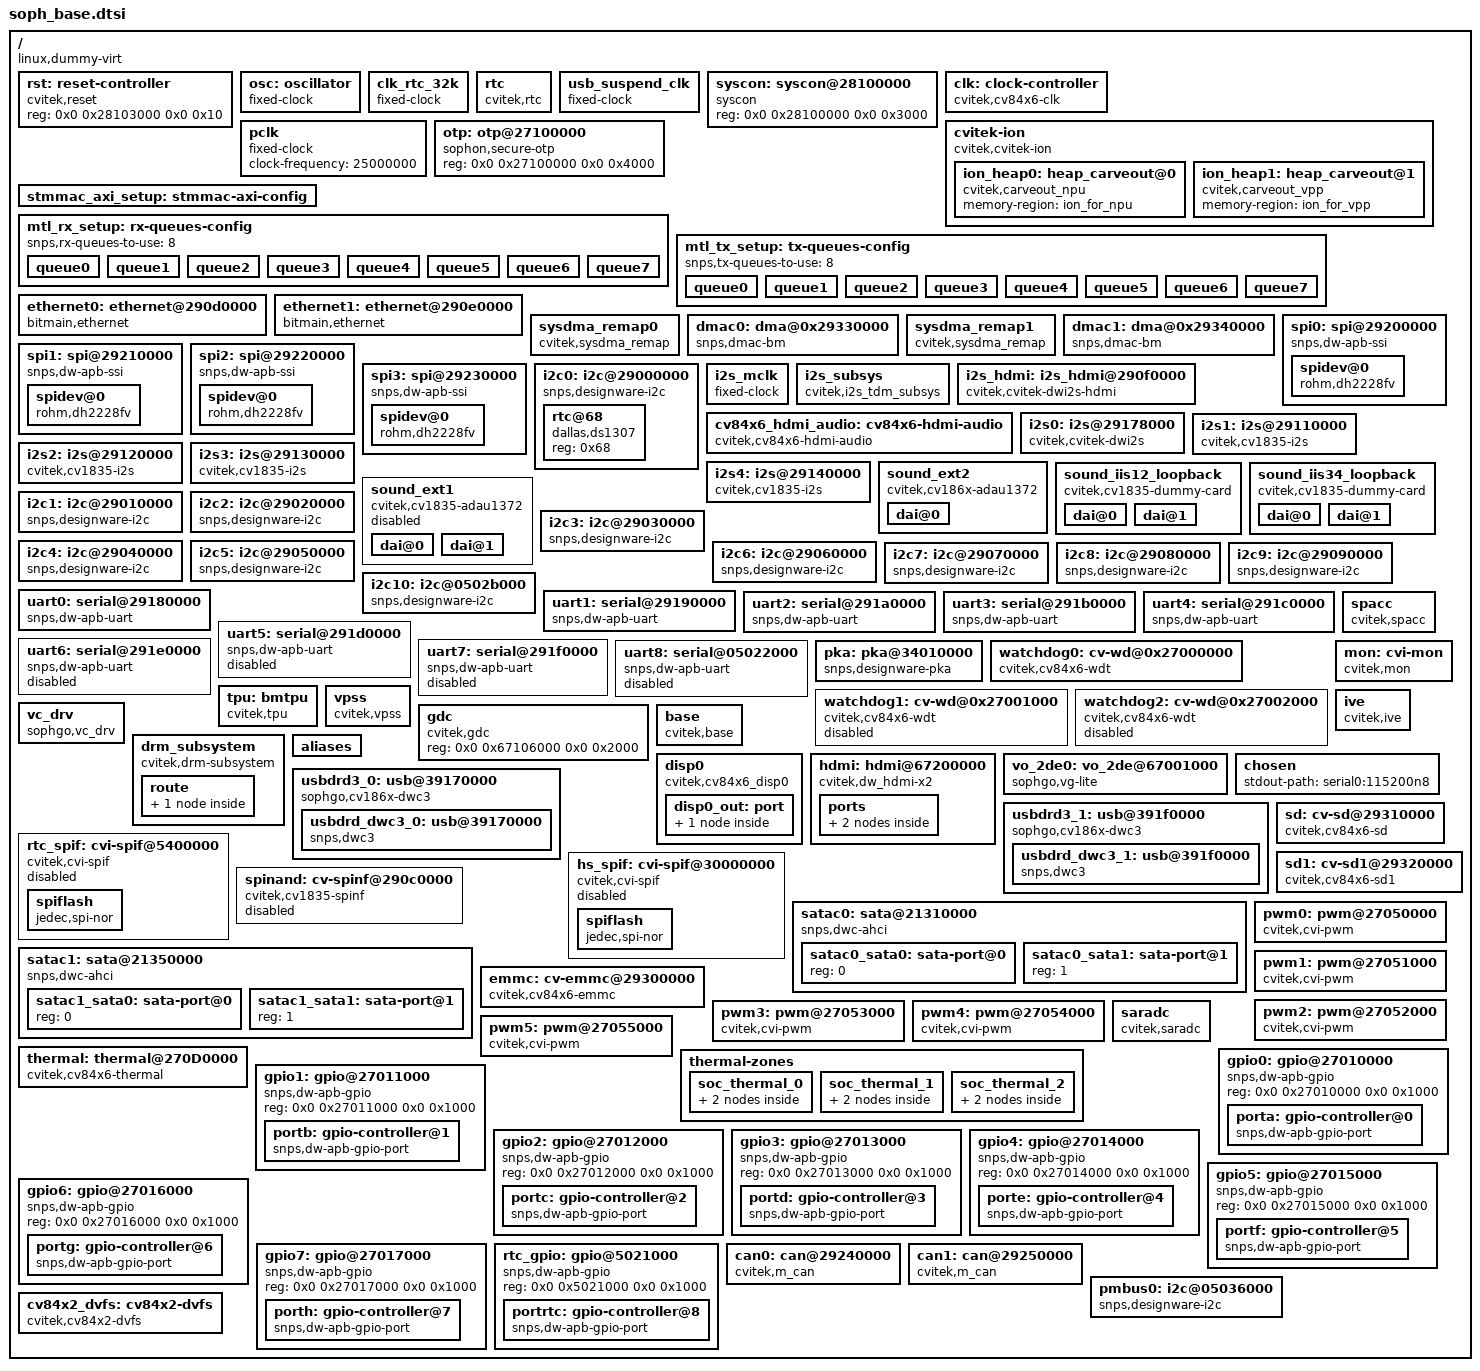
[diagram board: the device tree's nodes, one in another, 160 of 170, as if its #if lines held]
#include <dt-bindings/interrupt-controller/arm-gic.h>
#include <dt-bindings/gpio/gpio.h>
#include <dt-bindings/clock/cv84x6-clock.h>
#include <dt-bindings/reset/cv186x-resets.h>
#include <dt-bindings/dma/cv84x6-dmamap.h>

#include "cv84x6-pinctrl.dtsi"
#include "cv84x6-pcie.dtsi"

/ {
	compatible = "linux,dummy-virt";
	#size-cells = <0x2>;
	#address-cells = <0x2>;

	serial-number = "FFFFFFFFFFFFFFFFFFFFFFFFFFFFFFFF";

	rst: reset-controller {
		#reset-cells = <1>;
		compatible = "cvitek,reset";
		reg = <0x0 0x28103000 0x0 0x10>;
	};

	osc: oscillator {
		#clock-cells = <0>;
		compatible = "fixed-clock";
		clock-frequency = <25000000>;
		clock-output-names = "osc";
	};

	clk_rtc_32k: clk_rtc_32k {
		#clock-cells = <0>;
		compatible = "fixed-clock";
		clock-frequency = <32768>;
		clock-output-names = "clk_rtc_32k";
	};

	rtc {
		compatible = "cvitek,rtc";
		reg = <0x0 0x05026000 0x0 0xF00>, <0x0 0x05025000 0x0 0x1000>;
	};

	usb_suspend_clk: usb_suspend_clk {
		#clock-cells = <0>;
		compatible = "fixed-clock";
		clock-frequency = <200000>;
		clock-output-names = "usb_suspend_clk";
	};

	syscon: syscon@28100000 {
		compatible = "syscon", "simple-mfd";
		reg = <0x0 0x28100000 0x0 0x3000>;
	};

	clk: clock-controller {
		compatible = "cvitek,cv84x6-clk";
		clocks = <&osc>;
		#clock-cells = <1>;
		syscon = <&syscon>;
	};

#ifndef __UBOOT__
	cvitek-ion {
		compatible = "cvitek,cvitek-ion";

		ion_heap0: heap_carveout@0 {
			compatible = "cvitek,carveout_npu";
			memory-region = <&ion_for_npu>;
		};

		ion_heap1: heap_carveout@1 {
			compatible = "cvitek,carveout_vpp";
			memory-region = <&ion_for_vpp>;
		};
	};
#endif

	pclk: pclk {
		#clock-cells = <0>;
		compatible = "fixed-clock";
		clock-frequency = <25000000>;
	};

	otp: otp@27100000 {
                compatible = "sophon,secure-otp";
                reg = <0x0 0x27100000 0x0 0x4000>;
                #address-cells = <1>;
                #size-cells = <1>;
        };

	stmmac_axi_setup: stmmac-axi-config {
		snps,wr_osr_lmt = <1>;
		snps,rd_osr_lmt = <2>;
		snps,blen = <4 8 16 0 0 0 0>;
	};

	mtl_rx_setup: rx-queues-config {
		snps,rx-queues-to-use = <8>;
		queue0 {};
		queue1 {};
		queue2 {};
		queue3 {};
		queue4 {};
		queue5 {};
		queue6 {};
		queue7 {};
	};

	mtl_tx_setup: tx-queues-config {
		snps,tx-queues-to-use = <8>;
		queue0 {};
		queue1 {};
		queue2 {};
		queue3 {};
		queue4 {};
		queue5 {};
		queue6 {};
		queue7 {};
	};

	ethernet0: ethernet@290d0000 {
		compatible = "bitmain,ethernet";
		reg = <0x0 0x290d0000 0x0 0x4000>;
		reg-names = "mac";

		clock-names = "clk_tx", "stmmaceth", "ptp_ref";
		clocks = <&clk CV84X6_CLK_ETH0_TX>,
			   <&clk CV84X6_CLK_AXI4_ETH0>,
			   <&clk CV84X6_CLK_ETH0_PTP_REF>;
		// resets= <&rst RST_ETH0>;
		// reset-names = "stmmaceth";
#ifdef __UBOOT__
		phy-reset-gpios = <&porta 6 0>;
#endif
		/* no hash filter and perfect filter support */
		snps,multicast-filter-bins = <0>;
		snps,perfect-filter-entries = <1>;

		snps,txpbl = <32>;
		snps,rxpbl = <32>;
		snps,aal;

		snps,axi-config = <&stmmac_axi_setup>;
		snps,mtl-rx-config = <&mtl_rx_setup>;
		snps,mtl-tx-config = <&mtl_tx_setup>;

		phy-mode = "rgmii-id";
		//phy-mode = "rgmii_txid";

		status = "okay";
	};

	ethernet1: ethernet@290e0000 {
		compatible = "bitmain,ethernet";
		reg = <0x0 0x290e0000 0x0 0x4000>;
		reg-names = "mac";

		clock-names = "clk_tx", "stmmaceth", "ptp_ref";
		clocks = <&clk CV84X6_CLK_ETH1_TX>,
			   <&clk CV84X6_CLK_AXI4_ETH1>,
			   <&clk CV84X6_CLK_ETH1_PTP_REF>;
		// resets= <&rst RST_ETH0>;
		// reset-names = "stmmaceth";
#ifdef __UBOOT__
		phy-reset-gpios = <&porta 7 0>;
#endif
		/* no hash filter and perfect filter support */
		snps,multicast-filter-bins = <0>;
		snps,perfect-filter-entries = <1>;

		snps,txpbl = <32>;
		snps,rxpbl = <32>;
		snps,aal;

		snps,axi-config = <&stmmac_axi_setup>;
		snps,mtl-rx-config = <&mtl_rx_setup>;
		snps,mtl-tx-config = <&mtl_tx_setup>;

		phy-mode = "rgmii-id";
		//phy-mode = "rgmii_txid";

		status = "okay";
	};

	sysdma_remap0 {
		compatible = "cvitek,sysdma_remap";
		reg = <0x0 0x28100364 0x0 0x8>;

		ch-remap = <CVI_I2S0_RX CVI_I2S2_TX CVI_I2S1_RX CVI_I2S1_TX
					CVI_I2S_dw_RX CVI_I2S_dw_TX CVI_I2S2_RX CVI_I2S3_TX>;
	};

	dmac0: dma@0x29330000 {
		compatible = "snps,dmac-bm";
		reg = <0x0 0x29330000 0x0 0x1000>;
		clock-names = "clk_sdma_axi";
		clocks = <&clk CV84X6_CLK_AXI_SDMA0>;
		dma-channels = /bits/ 8 <8>;
		#dma-cells = <3>;
		dma-requests = /bits/ 8 <16>;
		chan_allocation_order = /bits/ 8 <0>;
		chan_priority = /bits/ 8 <1>;
		block_size = <1024>;
		dma-masters = /bits/ 8 <2>;
		data-width = <4 4>; /* bytes */
		axi_tr_width = <4>; /* bytes */
		block-ts = <15>;
	};

	sysdma_remap1 {
		compatible = "cvitek,sysdma_remap";
		reg = <0x0 0x2810036C 0x0 0x8>;
		ch-remap = <CVI_I2S4_RX CVI_SPI_NAND CVI_SPI_NAND CVI_I2S5_TX
					CVI_SPI0_RX CVI_SPI0_TX CVI_SPI1_RX CVI_SPI1_TX>;
	};

	dmac1: dma@0x29340000 {
		compatible = "snps,dmac-bm";
		reg = <0x0 0x29340000 0x0 0x1000>;
		clock-names = "clk_sdma_axi";
		clocks = <&clk CV84X6_CLK_AXI_SDMA1>;
		dma-channels = /bits/ 8 <8>;
		#dma-cells = <3>;
		dma-requests = /bits/ 8 <16>;
		chan_allocation_order = /bits/ 8 <0>;
		chan_priority = /bits/ 8 <1>;
		block_size = <1024>;
		dma-masters = /bits/ 8 <2>;
		data-width = <4 4>; /* bytes */
		axi_tr_width = <4>; /* bytes */
		block-ts = <15>;
	};

	spi0:spi@29200000 {
		compatible = "snps,dw-apb-ssi";
		reg = <0x0 0x29200000 0x0 0x10000>;
		clocks = <&clk CV84X6_CLK_SPI0>;
		#address-cells = <1>;
		#size-cells = <0>;
#if 0
		dmas = <&dmac1 4 1 1
			&dmac1 5 1 1>;
		dma-names = "rx", "tx";
		capability = "rxtx";
#endif
		status = "okay";
		num-cs = <1>;
		spidev@0 {
			compatible = "rohm,dh2228fv";
			spi-max-frequency = <1000000>;
			reg = <0>;
		};
	};

	spi1:spi@29210000 {
		compatible = "snps,dw-apb-ssi";
		reg = <0x0 0x29210000 0x0 0x10000>;
		clocks = <&clk CV84X6_CLK_SPI1>;
		#address-cells = <1>;
		#size-cells = <0>;
#if 0
		dmas = <&dmac1 6 1 1
			&dmac1 7 1 1>;
		dma-names = "rx", "tx";
		capability = "rxtx";
#endif
		status = "okay";
		num-cs = <1>;
		spidev@0 {
			compatible = "rohm,dh2228fv";
			spi-max-frequency = <1000000>;
			reg = <0>;
		};
	};

	spi2:spi@29220000 {
		compatible = "snps,dw-apb-ssi";
		reg = <0x0 0x29220000 0x0 0x10000>;
		clocks = <&clk CV84X6_CLK_SPI2>;
		#address-cells = <1>;
		#size-cells = <0>;
		status = "okay";
		num-cs = <1>;
		spidev@0 {
			compatible = "rohm,dh2228fv";
			spi-max-frequency = <1000000>;
			reg = <0>;
		};
	};

	spi3:spi@29230000 {
		compatible = "snps,dw-apb-ssi";
		reg = <0x0 0x29230000 0x0 0x10000>;
		clocks = <&clk CV84X6_CLK_SPI3>;
		#address-cells = <1>;
		#size-cells = <0>;
		status = "okay";
		num-cs = <1>;
		spidev@0 {
			compatible = "rohm,dh2228fv";
			spi-max-frequency = <1000000>;
			reg = <0>;
		};
	};

	i2c0: i2c@29000000 {
		compatible = "snps,designware-i2c";
		clocks = <&clk CV84X6_CLK_I2C0>;
		reg = <0x0 0x29000000 0x0 0x1000>;
		clock-frequency = <100000>;

		#size-cells = <0x0>;
		#address-cells = <0x1>;
		// resets = <&rst RST_I2C0>;
		// reset-names = "i2c0";

		pinctrl-names = "default";
		pinctrl-0 = <&i2c0_default>;

		rtc@68 {
			compatible = "dallas,ds1307";
			reg = <0x68>;
		};
	};

	i2s_mclk: i2s_mclk {
		clock-output-names = "i2s_mclk";
		clock-frequency = <24576000>;
		#clock-cells = <0x0>;
		compatible = "fixed-clock";
	};

	i2s_subsys: i2s_subsys {
		compatible = "cvitek,i2s_tdm_subsys";
		reg = <0x0 0x29100000 0x0 0x10000>;
		clocks = <&i2s_mclk>,
			<&clk CV84X6_CLK_AUD0>, <&clk CV84X6_CLK_AUD1>,
			<&clk CV84X6_CLK_AUD2>, <&clk CV84X6_CLK_AUD3>,
			<&clk CV84X6_CLK_AUD4>, <&clk CV84X6_CLK_AUD_HDMI>;

		clock-names = "i2sclk",
			"clk_aud0", "clk_aud1",
			"clk_aud2", "clk_aud3",
			"clk_aud4";
		master_base = <0x29110000>; /* I2S1 is master, only useful while using multi I2S IPs work on same IO */
	};

	i2s_hdmi: i2s_hdmi@290f0000 {
		compatible = "cvitek,cvitek-dwi2s-hdmi";
		reg = <0x0 0x290f0000 0x0 0x10000>,
		      <0x0 0x28102000 0x0 0x400>;
		clocks = <&clk CV84X6_CLK_AUD_HDMI>;
		clock-names = "hdmi_aud_clk";
		dev-id = <0>;
		#sound-dai-cells = <0>;
		dmas = <&dmac1 2 1 1>;
		dma-names = "tx";
		capability = "tx";
		mclk_out = "true";
		status = "okay";
	};

#ifndef __UBOOT__
	cv84x6_hdmi_audio: cv84x6-hdmi-audio {
		compatible = "cvitek,cv84x6-hdmi-audio";
		cvi,card_name = "cv84x6-hdmi";
		cvi,cpu_dai_name = "290f0000.i2s_hdmi";
		cvi,platform_name = "290f0000.i2s_hdmi";
		cvi,codec = <&hdmi>;
		status = "okay";
	};
#endif

	i2s0: i2s@29178000 {
		compatible = "cvitek,cvitek-dwi2s";
		reg = <0x0 0x29178000 0x0 0x400>;
		clocks = <&i2s_mclk 0>;
		clock-names = "i2sclk";

		dev-id = <6>;
		#sound-dai-cells = <0>;
		dmas = <&dmac0 0 1 1    /* read channel */
				&dmac0 1 1 1>;  /* write channel */
		dma-names = "rx","tx";
		capability = "txrx"; /* I2S0 connect to internal ADC as RX */
		mclk_out = "true";

		pinctrl-names = "default";
		pinctrl-0 = <&i2s0_default>;
	};

	i2s1: i2s@29110000 {
		compatible = "cvitek,cv1835-i2s";
		reg = <0x0 0x29110000 0x0 0x10000>;
		clocks = <&i2s_mclk 0>;
		clock-names = "i2sclk";

		dev-id = <0>;
		#sound-dai-cells = <0>;
		dmas = <&dmac0 2 1 1>; /* CVI_I2S1_RX=2, sysdma_remap0 ch2 (Case A reversed) */
		dma-names = "rx";
		capability = "rx"; /* Case A reversed: IIS1 slave RX <- IIS2 master TX */
		mclk_out = "false";

		pinctrl-names = "default";
		pinctrl-0 = <&i2s1_default>;
	};

	i2s2: i2s@29120000 {
		compatible = "cvitek,cv1835-i2s";
		reg = <0x0 0x29120000 0x0 0x10000>;
		clocks = <&i2s_mclk 0>;
		clock-names = "i2sclk";

		dev-id = <1>;
		#sound-dai-cells = <0>;
		dmas = <&dmac0 3 1 1>; /* CVI_I2S2_TX=5, sysdma_remap0 ch3 (Case A reversed) */
		dma-names = "tx";
		capability = "tx"; /* Case A reversed: IIS2 master TX -> IIS1 slave RX */
		mclk_out = "true";
	};

	i2s3: i2s@29130000 {
		compatible = "cvitek,cv1835-i2s";
		reg = <0x0 0x29130000 0x0 0x10000>;
		clocks = <&i2s_mclk 0>;
		clock-names = "i2sclk";

		dev-id = <2>;
		#sound-dai-cells = <0>;
		dmas = <&dmac0 4 1 1>; /* write channel */
		dma-names = "tx";
		capability = "tx"; /* Case B: IIS3 slave TX <- IIS4 master RX (internal loopback) */
		mclk_out = "false";
	};

	i2s4: i2s@29140000 {
		compatible = "cvitek,cv1835-i2s";
		reg = <0x0 0x29140000 0x0 0x10000>;
		clocks = <&i2s_mclk 0>;
		clock-names = "i2sclk";

		dev-id = <3>;
		#sound-dai-cells = <0>;
		dmas = <&dmac1 0 1 1>; /* read channel: dmac1 ch0 = CVI_I2S4_RX per sysdma_remap1 */
		dma-names = "rx";
		capability = "rx"; /* Case B: IIS4 master RX -> IIS3 slave TX (internal loopback, duplex variant: 0x70/0x74) */
		mclk_out = "true";
	};

	sound_ext2 {
		compatible = "cvitek,cv186x-adau1372";
		cvi,model = "CV1835";
		cvi,mode = "I2S";
		cvi,fmt = "NBNF";
		cvi,card_name = "cvi_cv186x_dw";
		cvi,slot_no=<2>;

		dai@0 {
			cvi,stream_name = "adau1372-aif";
			cvi,role = "master";
		};
	};

	/* Case A: IIS1 master TX + IIS2 slave RX, IIS1 PAD SDO<->SDI externally shorted */
	sound_iis12_loopback {
		compatible = "cvitek,cv1835-dummy-card";
		cvi,model = "CV1835";
		cvi,mode = "I2S";
		cvi,fmt = "IBNF";
		cvi,card_name = "iis12_loopback";
		cvi,slot_no = <2>;
		status = "okay"; /* Case A: IIS1/2 external pad loopback */

		/* audio_sys mux: IIS1 (tdm_0) slave RX takes SCLK/FS/SDI from IIS2 (tdm_1) master TX.
		 * X2 audio_sys mux only supports "from next IIS(N+1)" routing, so Case A direction
		 * is reversed: IIS2 master TX → IIS1 slave RX (cv84x2 bmtest line 1528 reference).
		 * tdm_0[1:0]=01 for SCLK/FS, tdm_1[3:2]=01 for SDI. */
		cvi,loopback-mux = <&i2s_subsys
			0x00 0xFF 0x01   /* SCLK_IN_SEL: tdm_0=01 <- IIS2 bclk_out */
			0x04 0xFF 0x01   /* FS_IN_SEL:   tdm_0=01 <- IIS2 ws_lrck_fs_out */
			0x08 0xFF 0x01   /* SDI_IN_SEL:  tdm_1=01 <- IIS2 sdo (IIS1 SDI from IIS2 SDO, from-next routing) */
			0x0C 0xFF 0x00   /* SDO_OUT_SEL: no pad output needed */
			0x30 0xFF 0x00   /* BCLK_OEN_SEL: internal oen */>;

		/* IIS2 master TX (reversed: was IIS1 master TX) */
		dai@0 {
			cvi,dai_name = "i2s2-tx";
			cvi,stream_name = "iis2-playback";
			cvi,cpu_dai_name = "29120000.i2s";
			cvi,codec_dai_name = "dummy_codec-aif.0";
			cvi,platform_name = "29120000.i2s";
			cvi,codec_name = "dummy_codec.0";
			cvi,role = "master";
			cvi,playback_only;
		};

		/* IIS1 slave RX (reversed: was IIS2 slave RX) */
		dai@1 {
			cvi,dai_name = "i2s1-rx";
			cvi,stream_name = "iis1-capture";
			cvi,cpu_dai_name = "29110000.i2s";
			cvi,codec_dai_name = "dummy_codec-aif.0";
			cvi,platform_name = "29110000.i2s";
			cvi,codec_name = "dummy_codec.0";
			cvi,role = "slave";
			cvi,capture_only;
		};
	};

	/* Case B reversed: IIS3 master TX + IIS4 slave RX, fully internal (no pad) */
	sound_iis34_loopback {
		compatible = "cvitek,cv1835-dummy-card";
		cvi,model = "CV1835";
		cvi,mode = "I2S";
		cvi,fmt = "IBNF";
		cvi,card_name = "iis34_loopback";
		cvi,slot_no = <2>;
		status = "okay"; /* Case B: IIS3 slave TX <- IIS4 master RX (internal loopback) */

		/* audio_sys mux: tdm_3 takes tdm_4 bclk/ws; tdm_4 sdi <- tdm_3 sdo; no pad */
		cvi,loopback-mux = <&i2s_subsys
			0x00 0x30 0x30   /* i2s_tdm_sclk_in_sel: tdm_3[5:4]=11 <- tdm_4 bclk_out */
			0x04 0x30 0x30   /* i2s_tdm_fs_in_sel:   tdm_3[5:4]=11 <- tdm_4 ws_lrck */
			0x08 0xC0 0xC0   /* i2s_tdm_sdi_in_sel:  tdm_4[7:6]=11 <- tdm_3 sdo */
			0x0C 0xFF 0x00   /* i2s_tdm_sdo_out_sel: no pad output */
			0x20 0xFF 0x00   /* i2s_tdm_multi_sync0 */
			0x24 0xFF 0x00   /* i2s_tdm_multi_sync1 */>;

		/* IIS3 slave TX */
		dai@0 {
			cvi,dai_name = "i2s3-tx";
			cvi,stream_name = "iis3-playback";
			cvi,cpu_dai_name = "29130000.i2s";
			cvi,codec_dai_name = "dummy_codec-aif.1";
			cvi,platform_name = "29130000.i2s";
			cvi,codec_name = "dummy_codec.1";
			cvi,role = "slave";
			cvi,playback_only;
		};

		/* IIS4 master RX */
		dai@1 {
			cvi,dai_name = "i2s4-rx";
			cvi,stream_name = "iis4-capture";
			cvi,cpu_dai_name = "29140000.i2s";
			cvi,codec_dai_name = "dummy_codec-aif.1";
			cvi,platform_name = "29140000.i2s";
			cvi,codec_name = "dummy_codec.1";
			cvi,role = "master";
			cvi,capture_only;
		};
	};

	sound_ext1 {
		compatible = "cvitek,cv1835-adau1372";
		cvi,model = "CV1835";
		cvi,mode = "I2S";
		cvi,fmt = "IBNF";
		cvi,card_name = "cvi_sound_card_0";
		cvi,slot_no=<2>;
		status = "disabled"; /* conflicts with sound_iis12_loopback (IIS1) and sound_iis34_loopback (IIS3) */

		dai@0 {
			cvi,dai_name = "cv1835-i2s-3";
			cvi,stream_name = "adau1372-aif";
			cvi,cpu_dai_name = "29130000.i2s";
			cvi,codec_dai_name = "adau1372-aif";
			cvi,platform_name = "29130000.i2s";
			cvi,codec_name = "adau1372.0-003c";
			cvi,role = "slave";
			cvi,capture_only;
		};

		dai@1 {
			cvi,dai_name = "cv1835-i2s-1";
			cvi,stream_name = "adau1372-aif";
			cvi,cpu_dai_name = "29110000.i2s";
			cvi,codec_dai_name = "adau1372-aif";
			cvi,platform_name = "29110000.i2s";
			cvi,codec_name = "adau1372.0-003c";
			cvi,role = "master";
			cvi,playback_only;
		};
	};

	i2c1: i2c@29010000 {
		compatible = "snps,designware-i2c";
		clocks = <&clk CV84X6_CLK_I2C1>;
		reg = <0x0 0x29010000 0x0 0x1000>;
		clock-frequency = <400000>;

		#size-cells = <0x0>;
		#address-cells = <0x1>;
		// resets = <&rst RST_I2C1>;
		// reset-names = "i2c1";
	};

	i2c2: i2c@29020000 {
		compatible = "snps,designware-i2c";
		clocks = <&clk CV84X6_CLK_I2C2>;
		reg = <0x0 0x29020000 0x0 0x1000>;
		clock-frequency = <100000>;

		#size-cells = <0x0>;
		#address-cells = <0x1>;
		// resets = <&rst RST_I2C2>;
		// reset-names = "i2c2";
	};

	i2c3: i2c@29030000 {
		compatible = "snps,designware-i2c";
		clocks = <&clk CV84X6_CLK_I2C3>;
		reg = <0x0 0x29030000 0x0 0x1000>;
		clock-frequency = <400000>;

		#size-cells = <0x0>;
		#address-cells = <0x1>;
		// resets = <&rst RST_I2C3>;
		// reset-names = "i2c3";
	};

	i2c4: i2c@29040000 {
		compatible = "snps,designware-i2c";
		clocks = <&clk CV84X6_CLK_I2C4>;
		reg = <0x0 0x29040000 0x0 0x1000>;
		clock-frequency = <400000>;

		#size-cells = <0x0>;
		#address-cells = <0x1>;
		// resets = <&rst RST_I2C4>;
		// reset-names = "i2c4";
	};

	i2c5: i2c@29050000 {
		compatible = "snps,designware-i2c";
		clocks = <&clk CV84X6_CLK_I2C5>;
		reg = <0x0 0x29050000 0x0 0x1000>;
		// clock-frequency = <400000>;
		clock-frequency = <1000000>;

		#size-cells = <0x0>;
		#address-cells = <0x1>;
		// resets = <&rst RST_I2C5>;
		// reset-names = "i2c5";
	};

	i2c6: i2c@29060000 {
		compatible = "snps,designware-i2c";
		clocks = <&clk CV84X6_CLK_I2C6>;
		reg = <0x0 0x29060000 0x0 0x1000>;
		clock-frequency = <400000>;

		#size-cells = <0x0>;
		#address-cells = <0x1>;
		// resets = <&rst RST_I2C6>;
		// reset-names = "i2c6";
	};

	i2c7: i2c@29070000 {
		compatible = "snps,designware-i2c";
		clocks = <&clk CV84X6_CLK_I2C7>;
		reg = <0x0 0x29070000 0x0 0x1000>;
		clock-frequency = <400000>;

		#size-cells = <0x0>;
		#address-cells = <0x1>;
		// resets = <&rst RST_I2C7>;
		// reset-names = "i2c7";
	};

	i2c8: i2c@29080000 {
		compatible = "snps,designware-i2c";
		clocks = <&clk CV84X6_CLK_I2C8>;
		reg = <0x0 0x29080000 0x0 0x1000>;
		clock-frequency = <400000>;

		#size-cells = <0x0>;
		#address-cells = <0x1>;
		// resets = <&rst RST_I2C8>;
		// reset-names = "i2c8";
	};

	i2c9: i2c@29090000 {
		compatible = "snps,designware-i2c";
		clocks = <&clk CV84X6_CLK_I2C9>;
		reg = <0x0 0x29090000 0x0 0x1000>;
		clock-frequency = <400000>;

		#size-cells = <0x0>;
		#address-cells = <0x1>;
		// resets = <&rst RST_I2C9>;
		// reset-names = "i2c9";
	};

	i2c10: i2c@0502b000 {
		compatible = "snps,designware-i2c";
		clocks = <&clk CV84X6_CLK_XTAL_MISC>;
		reg = <0x0 0x0502b000 0x0 0x1000>;
		clock-frequency = <400000>;

		#size-cells = <0x0>;
		#address-cells = <0x1>;
	};

	uart0: serial@29180000 {
		compatible = "snps,dw-apb-uart";
		reg = <0x0 0x29180000 0x0 0x1000>;
		clock-frequency = <200000000>;
		current-speed = <115200>;
		reg-shift = <2>;
		reg-io-width = <4>;
		status = "okay";
	};

	uart1: serial@29190000 {
		compatible = "snps,dw-apb-uart";
		reg = <0x0 0x29190000 0x0 0x1000>;
		clock-frequency = <200000000>;
		reg-shift = <2>;
		reg-io-width = <4>;
		status = "okay";
	};

	uart2: serial@291a0000 {
		compatible = "snps,dw-apb-uart";
		reg = <0x0 0x291a0000 0x0 0x1000>;
		clock-frequency = <200000000>;
		reg-shift = <2>;
		reg-io-width = <4>;
		status = "okay";
	};

	uart3: serial@291b0000 {
		compatible = "snps,dw-apb-uart";
		reg = <0x0 0x291b0000 0x0 0x1000>;
		clock-frequency = <200000000>;
		reg-shift = <2>;
		reg-io-width = <4>;
		status = "okay";
	};

	uart4: serial@291c0000 {
		compatible = "snps,dw-apb-uart";
		reg = <0x0 0x291c0000 0x0 0x1000>;
		clock-frequency = <200000000>;
		reg-shift = <2>;
		reg-io-width = <4>;
		status = "okay";
	};

	uart5: serial@291d0000 {
		compatible = "snps,dw-apb-uart";
		reg = <0x0 0x291d0000 0x0 0x1000>;
		clock-frequency = <200000000>;
		reg-shift = <2>;
		reg-io-width = <4>;
		status = "disabled";
	};

	uart6: serial@291e0000 {
		compatible = "snps,dw-apb-uart";
		reg = <0x0 0x291e0000 0x0 0x1000>;
		clock-frequency = <200000000>;
		reg-shift = <2>;
		reg-io-width = <4>;
		status = "disabled";
	};

	uart7: serial@291f0000 {
		compatible = "snps,dw-apb-uart";
		reg = <0x0 0x291f0000 0x0 0x1000>;
		clock-frequency = <200000000>;
		reg-shift = <2>;
		reg-io-width = <4>;
		status = "disabled";
	};

	uart8: serial@05022000 {
		compatible = "snps,dw-apb-uart";
		reg = <0x0 0x05022000 0x0 0x1000>;
		clock-frequency = <25000000>;
		reg-shift = <2>;
		reg-io-width = <4>;
		status = "disable";
	};

	pka: pka@34010000 {
		compatible = "snps,designware-pka";
		reg = <0x00000000 0x34010000 0x00000000 0x00010000>;
		bus-width = <4>;
		// resets-names = "pka";
		// resets = <&rst RST_PKA>;

		// clock-names = "pka";
		// clocks = <&div_clk GATE_CLK_AXI_PKA>;
		clock-frequency = <1400000000>;
	};
	spacc: spacc {
                compatible = "cvitek,spacc";
        };

	watchdog0: cv-wd@0x27000000 {
		compatible = "cvitek,cv84x6-wdt", "snps,dw-wdt";
		reg = <0x0 0x27000000 0x0 0x1000>;
		resets = <&rst RST_WDT0>;
		clocks = <&clk CV84X6_CLK_WDT>;
	};

	watchdog1: cv-wd@0x27001000 {
		compatible = "cvitek,cv84x6-wdt", "snps,dw-wdt";
		reg = <0x0 0x27001000 0x0 0x1000>;
		resets = <&rst RST_WDT1>;
		clocks = <&clk CV84X6_CLK_WDT>;
		status = "disabled";
	};

	watchdog2: cv-wd@0x27002000 {
		compatible = "cvitek,cv84x6-wdt", "snps,dw-wdt";
		reg = <0x0 0x27002000 0x0 0x1000>;
		resets = <&rst RST_WDT2>;
		clocks = <&clk CV84X6_CLK_WDT>;
		status = "disabled";
	};

	mon: cvi-mon {
		compatible = "cvitek,mon";
		reg-names = "f0s1", "f1s1", "f2s1", "f3s1", "f5s1",
					"ve", "vd0_mon0", "vd0_mon1", "vd1_mon0", "vd1_mon1",
					"vd2_mon0", "vd2_mon1", "vd3_mon0", "vd3_mon1",
					"vo_iga", "vo_off", "vo_rt",
					"tpu_mon0", "tpu_mon1", "tpu_mon2",
					"tpu_mon3", "tpu_mon4", "tpu_mon5",
					"ddr0_mon0", "ddr1_mon0", "ddr2_mon0", "ddr3_mon0",
				"ddr0_mon1", "ddr1_mon1", "ddr2_mon1", "ddr3_mon1";
		reg = <0x0 0x2813C000 0x0 0x1000>, /* F0S1 */
		      <0x0 0x2813D000 0x0 0x1000>, /* F1S1 */
		      <0x0 0x2813E000 0x0 0x1000>, /* F2S1 */
		      <0x0 0x2813F000 0x0 0x1000>, /* F3S1 */
		      <0x0 0x28140000 0x0 0x1000>, /* F5S1 */
		      <0x0 0x22070000 0x0 0x1000>, /* VE */
		      <0x0 0x23060000 0x0 0x1000>, /* VD0_MON0 */
		      <0x0 0x23061000 0x0 0x1000>, /* VD0_MON1 */
		      <0x0 0x23160000 0x0 0x1000>, /* VD1_MON0 */
		      <0x0 0x23161000 0x0 0x1000>, /* VD1_MON1 */
		      <0x0 0x23260000 0x0 0x1000>, /* VD2_MON0 */
		      <0x0 0x23261000 0x0 0x1000>, /* VD2_MON1 */
		      <0x0 0x23360000 0x0 0x1000>, /* VD3_MON0 */
		      <0x0 0x23361000 0x0 0x1000>, /* VD3_MON1 */
		      <0x0 0x67300000 0x0 0x1000>, /* VO_IGA (no IRQ) */
		      <0x0 0x67302000 0x0 0x1000>, /* VO_OFF (no IRQ) */
		      <0x0 0x67303000 0x0 0x1000>, /* VO_RT (no IRQ) */
		      <0x0 0x26F00000 0x0 0x1000>, /* TPU_MON0 (no IRQ) */
		      <0x0 0x26F01000 0x0 0x1000>, /* TPU_MON1 (no IRQ) */
		      <0x0 0x26F02000 0x0 0x1000>, /* TPU_MON2 (no IRQ) */
		      <0x0 0x26F03000 0x0 0x1000>, /* TPU_MON3 (no IRQ) */
		      <0x0 0x26F04000 0x0 0x1000>, /* TPU_MON4 (no IRQ) */
		      <0x0 0x26F05000 0x0 0x1000>, /* TPU_MON5 (no IRQ) */
			  <0x0 0x70c06000 0x0 0x100>, /* DDR0 - DDR SYS0 MON0 */
			  <0x0 0x74c06000 0x0 0x100>, /* DDR1 - DDR SYS1 MON0 */
			  <0x0 0x78c06000 0x0 0x100>, /* DDR2 - DDR SYS2 MON0 */
			  <0x0 0x7cc06000 0x0 0x100>, /* DDR3 - DDR SYS3 MON0 */
			  <0x0 0x70c06100 0x0 0x100>, /* DDR0 - DDR SYS0 MON1 */
			  <0x0 0x74c06100 0x0 0x100>, /* DDR1 - DDR SYS1 MON1 */
			  <0x0 0x78c06100 0x0 0x100>, /* DDR2 - DDR SYS2 MON1 */
			  <0x0 0x7cc06100 0x0 0x100>; /* DDR3 - DDR SYS3 MON1 */
		/*
		 * CA55 IRQ numbers for AXI Monitor (SPI interrupts)
		 * Each monitor has 2 IRQs: [WR, RD]
		 * F0S1-F5S1: Fabric S1 monitors
		 * VD0-VD3: Video Decoder monitors (MON0, MON1 each)
		 * VE: Video Encoder monitor
		 */
		status = "okay";
	};

#ifndef __UBOOT__
	tpu: bmtpu {
		compatible = "cvitek,tpu";
		reg = <0x0 0x20000000 0x0 0x19fffff>,
		      <0x0 0x24000000 0x0 0x2d11000>, // tpusys
		      <0x0 0x28100000 0x0 0x44fff>;
		/* 0x26F00000~0x26F0BFFF reserved for TPU monitors in cvi-mon */
		memory-region = <&ion_for_npu &ion_for_vpp &scaler_shm_reserved>;
		sophgo_c906_fw_mode = <1>;
	};
	vpss {
		compatible = "cvitek,vpss";
		reg =   <0x0 0x23020000 0x0 0x30000>,	//vpss_t0t1t2
				<0x0 0x23120000 0x0 0x30000>,	//vpss_t3t4t5
				<0x0 0x23220000 0x0 0x30000>,	//vpss_t6t7t8
				<0x0 0x23320000 0x0 0x30000>,	//vpss_t9t10t11
				<0x0 0x67110000 0x0 0x4000>;	//vpss_d
	};
	ive {
		compatible = "cvitek,ive";
		reg = 	<0x0 0x671D0000 0x0 0x10000>,
				<0x0 0x671E0000 0x0 0x10000>,
				<0x0 0x671F0000 0x0 0x10000>;
		reg-names = "ive_base0", "ive_base1", "ive_base2";
	};
	gdc {
		compatible = "cvitek,gdc";
		reg = <0x0 0x67106000 0x0 0x2000>;
		reg-names = "ldc0";
	};
	vc_drv {
		compatible = "sophgo,vc_drv";
		reg = 	<0x0 0x22020000 0x0 0x10000>,	//jpu
				<0x0 0x22030000 0x0 0x10000>,
				<0x0 0x22040000 0x0 0x10000>,
				<0x0 0x22010000 0x0 0x10000>,	//vpu
				<0x0 0x23010000 0x0 0x10000>,
				<0x0 0x23110000 0x0 0x10000>,
				<0x0 0x23210000 0x0 0x10000>,
				<0x0 0x23310000 0x0 0x10000>;
		/* clocks = <&clk CV186X_CLK_VESYS_JPEG_0>, <&clk CV186X_CLK_VESYS_JPEG_1>,
				<&clk CV186X_CLK_VESYS_JPEG_2>, <&clk CV186X_CLK_VESYS_JPEG_3>,
				<&clk CV186X_CLK_APB_VESYS_JPEG_0>, <&clk CV186X_CLK_APB_VESYS_JPEG_1>,
				<&clk CV186X_CLK_APB_VESYS_JPEG_2>, <&clk CV186X_CLK_APB_VESYS_JPEG_3>,
				<&clk CV186X_VE_CLK_SRC2_VESYS>, // jpeg
				<&clk CV186X_VE_CLK_SRC0_VESYS>, <&clk CV186X_VE_CLK_SRC1_VESYS>,
				<&clk CV186X_CLK_APB_VESYS_VE>, <&clk CV186X_CLK_VESYS_VE>,  // ve
				<&clk CV186X_VD0_CLK_SRC0_VDSYS>, <&clk CV186X_VD0_CLK_SRC1_VDSYS>,
				<&clk CV186X_VD1_CLK_SRC0_VDSYS>, <&clk CV186X_VD1_CLK_SRC1_VDSYS>,
				<&clk CV186X_VD0_CLK_APB_VDSYS_VD>, <&clk CV186X_VD0_CLK_VDSYS_VD>,
				<&clk CV186X_VD1_CLK_APB_VDSYS_VD>, <&clk CV186X_VD1_CLK_VDSYS_VD>;  // vd
		clock-names = "jpeg_vesys0", "jpeg_vesys1", "jpeg_vesys2", "jpeg_vesys3",
					"jpeg_apb0", "jpeg_apb1", "jpeg_apb2", "jpeg_apb3",
					"jpeg_src",  // jpeg
					"ve_src0", "ve_src1", "apb_vesys_ve", "clk_vesys_ve", // ve
					"vd0_src0", "vd0_src1", "vd1_src0", "vd1_src1",
					"vd0_apb_vd", "vd0_vdsys_vd",
					"vd1_apb_vd", "vd1_vdsys_vd"; //vd
		 */
	};

	base {
		compatible = "cvitek,base";
	};

	drm_subsystem: drm_subsystem {
		u-boot,dm-pre-reloc;
		compatible = "cvitek,drm-subsystem";
		reg = <0x0 0x67000000 0x0 0x4000>,
			  <0x0 0x28102000 0x0 0x400>,
			  <0x0 0x67110000 0x0 0x4000>,
			  <0x0 0x28100000 0x0 0x1000>;
		reg-names = "vo_sys_f", "sys_ctrl_clkgen_div", "vpss0", "sys_ctrl";
		ports = <&disp0_out>;
		status = "okay";
		route {
				route_hdmi: route-hdmi {
					status = "okay";
					logo,uboot = "soph_logo.bmp";
					logo,mode = "center";
					connector = <&disp0_out_hdmi>;
				};
			};
	};

	disp0: disp0 {
		compatible = "cvitek,cv84x6_disp0";
		interrupt-names = "disp0";
		status = "okay";

		disp0_out: port {
			#address-cells = <1>;
			#size-cells = <0>;
			disp0_out_hdmi: endpoint@0 {
				reg = <0>;
				remote-endpoint = <&hdmi_in_disp0>;
			};
		};
	};

	hdmi: hdmi@67200000 {
		compatible = "cvitek,dw_hdmi-x2";
		reg = <0x0 0x67200000 0x0 0x20000>,
		      <0x0 0x67220000 0x0 0x10000>,
		      <0x0 0x67280000 0x0 0x80000>;
		reg-names = "hdmi_tx_ctrl", "hdmi_top", "aks_phy";
		interrupt-names = "dw_hdmi";
		status = "okay";
		hpd_level = "high"; 		/* high: high hpd level; low: low hpd level */
		ddc-i2c-scl-high-time-ns = <4500>;
		ddc-i2c-scl-low-time-ns = <5200>;
		phy-table =
			<0  0x0007 0x0160 0x8d88>,
			<1  0x0007 0x0160 0x8d88>,
			<2  0x0007 0x0160 0x8d88>,
			<3  0x0007 0x0160 0x8d88>,
			<4  0x0007 0x0160 0x8d88>,
			<5  0x0007 0x0160 0x8d88>,
			<6  0x0000 0x0120 0x83F8>,
			<7  0x0000 0x0120 0x83F8>,
			<8  0x0000 0x0120 0x83F8>,
			<9  0x0000 0x0140 0x80F6>,
			<10 0x0000 0x0140 0x80F6>;

		ports {
			#address-cells = <1>;
			#size-cells = <0>;

			hdmi_in: port@0 {
				reg = <0>;
				hdmi_in_disp0: endpoint {
					remote-endpoint = <&disp0_out_hdmi>;
				};
			};
		};
	};

	vo_2de0: vo_2de@67001000 {
		compatible = "sophgo,vg-lite", "sophgo,vg-lite0";
		interrupt-names = "vo_2de_irq0", "vo_2de0";
		reg = <0x0 0x67001000 0x0 0x00001000>;
		reg-names = "iobase_vg";
		dev-id = <0>;
	};
#endif

	aliases {
		serial0 = &uart0;
		mmc0 = &emmc;
		mmc1 = &sd;
		ethernet0 = &ethernet0;
		ethernet1 = &ethernet1;
	};

	chosen {
		stdout-path = "serial0:115200n8";
	};

	usbdrd3_0: usb@39170000 {
		compatible = "sophgo,cv186x-dwc3";
		reg = <0x0 0x39200000 0x0 0x100>;
		#address-cells = <2>;
		#size-cells = <2>;
		ranges;
		status = "okay";
		vbus-gpio = <&portc 5 GPIO_ACTIVE_HIGH>;

		usbdrd_dwc3_0: usb@39170000 {
			compatible = "snps,dwc3";
			reg = <0x0 0x39170000 0x0 0x10000>;
			clocks = <&usb_suspend_clk>;
			clock-names = "suspend_clk";
			snps,parkmode-disable-ss-quirk;
#ifdef __UBOOT__
			dr_mode = "host";
#else
			dr_mode = "otg";
#endif
			role-switch-default-mode = "device";
			maximum-speed = "super-speed";
			usb-role-switch;
			status = "okay";
		};
	};

	usbdrd3_1: usb@391f0000 {
		compatible = "sophgo,cv186x-dwc3";
		reg = <0x0 0x39200100 0x0 0x100>;
		#address-cells = <2>;
		#size-cells = <2>;
		ranges;
		status = "okay";
		vbus-gpio = <&portc 6 GPIO_ACTIVE_HIGH>;

		usbdrd_dwc3_1: usb@391f0000 {
			compatible = "snps,dwc3";
			reg = <0x0 0x391f0000 0x0 0x10000>;
			clocks = <&usb_suspend_clk>;
			clock-names = "suspend_clk";
			snps,parkmode-disable-ss-quirk;
#ifdef __UBOOT__
			dr_mode = "host";
#else
			dr_mode = "otg";
#endif
			role-switch-default-mode = "host";
			maximum-speed = "super-speed";
			usb-role-switch;
			status = "okay";
		};
	};

	rtc_spif:cvi-spif@5400000  {
		compatible = "cvitek,cvi-spif";
		bus-num = <0>;
		reg = <0x0 0x5400000 0x0 0x400000>;
		status = "disabled";
		reg-names = "spif";
		sck-div = <3>;
		sck_mhz = <300>;
		spi-max-frequency = <75000000>;
		spiflash {
			compatible = "jedec,spi-nor";
			spi-rx-bus-width = <4>;
			spi-tx-bus-width = <4>;
		};
	};

	hs_spif:cvi-spif@30000000  {
		compatible = "cvitek,cvi-spif";
		bus-num = <0>;
		reg = <0x0 0x30000000 0x0 0x400000>;
		status = "disabled";
		reg-names = "spif";
		sck-div = <3>;
		sck_mhz = <300>;
		spi-max-frequency = <75000000>;
		spiflash {
			compatible = "jedec,spi-nor";
			spi-rx-bus-width = <4>;
			spi-tx-bus-width = <4>;
		};
	};

	spinand:cv-spinf@290c0000 {
		compatible = "cvitek,cv1835-spinf";
		reg = <0x0 0x290c0000 0x0 0x1000>;
		status = "disabled";
		reg-names = "core_mem";
		bus-width = <4>;
		dmas = <&dmac1 1 1 1
			&dmac1 2 1 1>;
		dma-names = "rx","tx";
	};

	satac0: sata@21310000 {
		compatible = "snps,dwc-ahci";
		reg = <0x0 0x21310000 0x0 0x40000>;
		status = "okay";
		ports-implemented = <3>;
		#address-cells = <1>;
		#size-cells = <0>;

		satac0_sata0: sata-port@0 {
			reg = <0>;
		};

		satac0_sata1: sata-port@1 {
			reg = <1>;
		};
	};

	satac1: sata@21350000 {
		compatible = "snps,dwc-ahci";
		reg = <0x0 0x21350000 0x0 0x40000>;
		status = "okay";
		ports-implemented = <3>;
		#address-cells = <1>;
		#size-cells = <0>;

		satac1_sata0: sata-port@0 {
			reg = <0>;
		};

		satac1_sata1: sata-port@1 {
			reg = <1>;
		};
	};

	emmc:cv-emmc@29300000 {
		compatible = "cvitek,cv84x6-emmc";
		reg = <0x0 0x29300000 0x0 0x10000>;
		reg-names = "core_mem";
		status = "okay";
		bus-width = <8>;
		non-removable;
		no-sdio;
		no-sd;
		clocks = <&clk CV84X6_CLK_EMMC>,
				<&clk CV84X6_CLK_EMMC_100K>,
				<&clk CV84X6_CLK_AXI4_EMMC>;
		clock-names = "core", "100k", "axi";
		src-frequency = <400000000>;
		min-frequency = <400000>;
		max-frequency = <200000000>;
		mmc-hs200-1_8v;
		mmc-hs400-1_8v;
		mmc-hs400-enhanced-strobe;
		64_addressing;
		reset_tx_rx_phy;
	};

	sd:cv-sd@29310000 {
		compatible = "cvitek,cv84x6-sd";
		reg = <0x0 0x29310000 0x0 0x10000>;
		reg-names = "core_mem";
		status = "okay";
		bus-width = <4>;
		cap-sd-highspeed;
		sd-uhs-sdr12;
		sd-uhs-sdr25;
		sd-uhs-sdr50;
		sd-uhs-sdr104;
		no-sdio;
		no-mmc;
		pinctrl-names = "default";
		pinctrl-0 = <&sd0_default>;
		/*
		 * Use hardware CD (SD0_CD_X via pinctrl). broken-cd forces
		 * endless poll to set_power spam when slot is empty.
		 */
		clocks = <&clk CV84X6_CLK_SD0>,
			 <&clk CV84X6_CLK_SD0_100K>,
			 <&clk CV84X6_CLK_AXI4_SD0>;
		clock-names = "core", "100k", "axi";
		src-frequency = <400000000>;	/* 400MHz matching ROM PLAT_SD_CLK */
		min-frequency = <200000>;
		max-frequency = <200000000>;
		64_addressing;
		pwr-gpios = <&portc 2 GPIO_ACTIVE_HIGH>;
	};

	sd1:cv-sd1@29320000 {
		compatible = "cvitek,cv84x6-sd1";
		reg = <0x0 0x29320000 0x0 0x10000>;
		reg-names = "core_mem";
		status = "okay";
		bus-width = <4>;
		cap-sd-highspeed;
		sd-uhs-sdr12;
		sd-uhs-sdr25;
		sd-uhs-sdr50;
		sd-uhs-sdr104;
		no-sdio;
		no-mmc;
		pinctrl-names = "default";
		pinctrl-0 = <&sd1_default>;
		clocks = <&clk CV84X6_CLK_SD1>,
			 <&clk CV84X6_CLK_SD1_100K>,
			 <&clk CV84X6_CLK_AXI4_SD1>;
		clock-names = "core", "100k", "axi";
		src-frequency = <400000000>;	/* 400MHz matching ROM PLAT_SD_CLK */
		min-frequency = <200000>;
		max-frequency = <200000000>;
		64_addressing;
		pwr-gpios = <&portc 1 GPIO_ACTIVE_HIGH>;
	};

	pwm0: pwm@27050000 {
		compatible = "cvitek,cvi-pwm";
		reg = <0x0 0x27050000 0x0 0x1000>;
		clocks = <&clk CV84X6_CLK_PWM>;
		#pwm-cells = <2>;
	};

	pwm1: pwm@27051000 {
		compatible = "cvitek,cvi-pwm";
		reg = <0x0 0x27051000 0x0 0x1000>;
		clocks = <&clk CV84X6_CLK_PWM>;
		#pwm-cells = <2>;
	};

	pwm2: pwm@27052000 {
		compatible = "cvitek,cvi-pwm";
		reg = <0x0 0x27052000 0x0 0x1000>;
		clocks = <&clk CV84X6_CLK_PWM>;
		#pwm-cells = <2>;
	};

	pwm3: pwm@27053000 {
		compatible = "cvitek,cvi-pwm";
		reg = <0x0 0x27053000 0x0 0x1000>;
		clocks = <&clk CV84X6_CLK_PWM>;
		#pwm-cells = <2>;
	};

	pwm4: pwm@27054000 {
		compatible = "cvitek,cvi-pwm";
		reg = <0x0 0x27054000 0x0 0x1000>;
		clocks = <&clk CV84X6_CLK_PWM>;
		#pwm-cells = <2>;
	};

	pwm5: pwm@27055000 {
		compatible = "cvitek,cvi-pwm";
		reg = <0x0 0x27055000 0x0 0x1000>;
		clocks = <&clk CV84X6_CLK_PWM>;
		cvitek,secure-smc;
		#pwm-cells = <2>;
	};

	saradc {
		compatible = "cvitek,saradc";
		reg-names = "top_domain_saradc", "rtc_domain_saradc";
		reg = <0x0 0x270E0000 0x0 0x1000>, <0x0 0x0502C000 0x0 0x1000>;
		clocks = <&clk CV84X6_CLK_SARADC>;
		clock-names = "clk_saradc";
		resets = <&rst RST_SARADC>;
		reset-names = "res_saradc";
	};

	thermal: thermal@270D0000 {
		compatible = "cvitek,cv84x6-thermal";
		reg = <0x0 0x270D0000 0x0 0x10000>;
		clocks = <&clk CV84X6_CLK_TEMPSEN>;
		clock-names = "clk_tempsen";
		reset-names = "tempsen";
		#thermal-sensor-cells = <1>;
	};
	thermal-zones {
		soc_thermal_0: soc_thermal_0 {
			polling-delay-passive = <1000>; /* milliseconds */
			polling-delay = <1000>; /* milliseconds */
			thermal-sensors = <&thermal 0>;

			trips {
				soc_thermal_crtical_0: soc_thermal_crtical_0 {
					temperature = <125000>; /* millicelsius */
					hysteresis = <0>; /* millicelsius */
					type = "critical";
				};
			};
		};

		soc_thermal_1: soc_thermal_1 {
			polling-delay-passive = <1000>;
			polling-delay = <1000>;
			thermal-sensors = <&thermal 1>;

			trips {
				soc_thermal_crtical_1: soc_thermal_crtical_1 {
					temperature = <125000>;
					hysteresis = <0>;
					type = "critical";
				};
			};
		};

		soc_thermal_2: soc_thermal_2 {
			polling-delay-passive = <1000>;
			polling-delay = <1000>;
			thermal-sensors = <&thermal 2>;

			trips {
				soc_thermal_crtical_2: soc_thermal_crtical_2 {
					temperature = <125000>;
					hysteresis = <0>;
					type = "critical";
				};
			};
		};
	};
	gpio0: gpio@27010000 {
		compatible = "snps,dw-apb-gpio";
		reg = <0x0 0x27010000 0x0 0x1000>;
		#address-cells = <1>;
		#size-cells = <0>;

		porta: gpio-controller@0 {
			compatible = "snps,dw-apb-gpio-port";
			bank-name = "porta";
			gpio-controller;
			#gpio-cells = <2>;
			ngpios = <32>;
			reg = <0>;
			interrupt-controller;
			#interrupt-cells = <2>;
		};
	};

	gpio1: gpio@27011000 {
		compatible = "snps,dw-apb-gpio";
		reg = <0x0 0x27011000 0x0 0x1000>;
		#address-cells = <1>;
		#size-cells = <0>;

		portb: gpio-controller@1 {
			compatible = "snps,dw-apb-gpio-port";
			bank-name = "portb";
			gpio-controller;
			#gpio-cells = <2>;
			ngpios = <32>;
			reg = <0>;
			interrupt-controller;
			#interrupt-cells = <2>;
		};
	};

	gpio2: gpio@27012000 {
		compatible = "snps,dw-apb-gpio";
		reg = <0x0 0x27012000 0x0 0x1000>;
		#address-cells = <1>;
		#size-cells = <0>;

		portc: gpio-controller@2 {
			compatible = "snps,dw-apb-gpio-port";
			bank-name = "portc";
			gpio-controller;
			#gpio-cells = <2>;
			ngpios = <32>;
			reg = <0>;
			interrupt-controller;
			#interrupt-cells = <2>;
		};
	};

	gpio3: gpio@27013000 {
		compatible = "snps,dw-apb-gpio";
		reg = <0x0 0x27013000 0x0 0x1000>;
		#address-cells = <1>;
		#size-cells = <0>;

		portd: gpio-controller@3 {
			compatible = "snps,dw-apb-gpio-port";
			bank-name = "portd";
			gpio-controller;
			#gpio-cells = <2>;
			ngpios = <32>;
			reg = <0>;
			interrupt-controller;
			#interrupt-cells = <2>;
		};
	};

	gpio4: gpio@27014000 {
		compatible = "snps,dw-apb-gpio";
		reg = <0x0 0x27014000 0x0 0x1000>;
		#address-cells = <1>;
		#size-cells = <0>;

		porte: gpio-controller@4 {
			compatible = "snps,dw-apb-gpio-port";
			bank-name = "porte";
			gpio-controller;
			#gpio-cells = <2>;
			ngpios = <32>;
			reg = <0>;
			interrupt-controller;
			#interrupt-cells = <2>;
		};
	};

	gpio5: gpio@27015000 {
		compatible = "snps,dw-apb-gpio";
		reg = <0x0 0x27015000 0x0 0x1000>;
		#address-cells = <1>;
		#size-cells = <0>;

		portf: gpio-controller@5 {
			compatible = "snps,dw-apb-gpio-port";
			bank-name = "portf";
			gpio-controller;
			#gpio-cells = <2>;
			ngpios = <32>;
			reg = <0>;
			interrupt-controller;
			#interrupt-cells = <2>;
		};
	};

	gpio6: gpio@27016000 {
		compatible = "snps,dw-apb-gpio";
		reg = <0x0 0x27016000 0x0 0x1000>;
		#address-cells = <1>;
		#size-cells = <0>;

		portg: gpio-controller@6 {
			compatible = "snps,dw-apb-gpio-port";
			bank-name = "portg";
			gpio-controller;
			#gpio-cells = <2>;
			ngpios = <32>;
			reg = <0>;
			interrupt-controller;
			#interrupt-cells = <2>;
		};
	};

	gpio7: gpio@27017000 {
		compatible = "snps,dw-apb-gpio";
		reg = <0x0 0x27017000 0x0 0x1000>;
		#address-cells = <1>;
		#size-cells = <0>;

		porth: gpio-controller@7 {
			compatible = "snps,dw-apb-gpio-port";
			bank-name = "porth";
			gpio-controller;
			#gpio-cells = <2>;
			ngpios = <32>;
			reg = <0>;
			interrupt-controller;
			#interrupt-cells = <2>;
		};
	};

	rtc_gpio: gpio@5021000 {
		compatible = "snps,dw-apb-gpio";
		reg = <0x0 0x5021000 0x0 0x1000>;
		#address-cells = <1>;
		#size-cells = <0>;

		portrtc: gpio-controller@8 {
			compatible = "snps,dw-apb-gpio-port";
			bank-name = "portrtc";
			gpio-controller;
			#gpio-cells = <2>;
			ngpios = <32>;
			reg = <0>;
			interrupt-controller;
			#interrupt-cells = <2>;
		};
	};

	can0: can@29240000 {
		compatible = "cvitek,m_can";
		reg = <0x0 0x29240000 0x0 0x400>, <0x0 0x29242000 0x0 0x4000>;
		reg-names = "m_can", "message_ram";
		clocks = <&clk CV84X6_CLK_APB_CAN0>,<&clk CV84X6_CLK_CAN0>;
		clock-names = "hclk", "cclk";
		cvitek,mram-cfg = <0x0 0 0 64 0 0 32 32>;
		status = "okay";
	};
	can1: can@29250000 {
		compatible = "cvitek,m_can";
		reg = <0x0 0x29250000 0x0 0x400>, <0x0 0x29252000 0x0 0x4000>;
		reg-names = "m_can", "message_ram";
		clocks = <&clk CV84X6_CLK_APB_CAN1>,<&clk CV84X6_CLK_CAN1>;
		clock-names = "hclk", "cclk";
		cvitek,mram-cfg = <0x0 0 0 64 0 0 32 32>;
		status = "okay";
	};

	pmbus0: i2c@05036000 {
		compatible = "snps,designware-i2c";
		reg = <0x0 0x05036000 0x0 0x1000>;
		clocks = <&clk CV84X6_CLK_XTAL_MISC>;
		clock-frequency = <100000>;
		interrupts = <GIC_SPI 29 IRQ_TYPE_LEVEL_HIGH>;
		#size-cells = <0x0>;
		#address-cells = <0x1>;
		pinctrl-names = "default";
		pinctrl-0 = <&pwr_pmbus0_default>;
		status = "okay";
	};

	cv84x2_dvfs: cv84x2-dvfs {
		compatible = "cvitek,cv84x2-dvfs";
		clocks = <&clk CV84X6_CLK_AP_CA55>, <&clk CV84X6_CLK_TPU_SYS>;
		clock-names = "cpu", "tpu";
		/* MPS MP2985B PMIC, PMBus I2C slave 0x20 */
		pmic-addr = <0x20>;
		/* PMBus PAGE: 0=CPU, 1=TPU  */
		cpu-rail-page = <0>;
		tpu-rail-page = <1>;
		/* Volt Limit 600-1200mV */
		cpu-volt-min-mv = <600>;
		cpu-volt-max-mv = <1200>;
		tpu-volt-min-mv = <600>;
		tpu-volt-max-mv = <1200>;
		status = "okay";
	};
};

